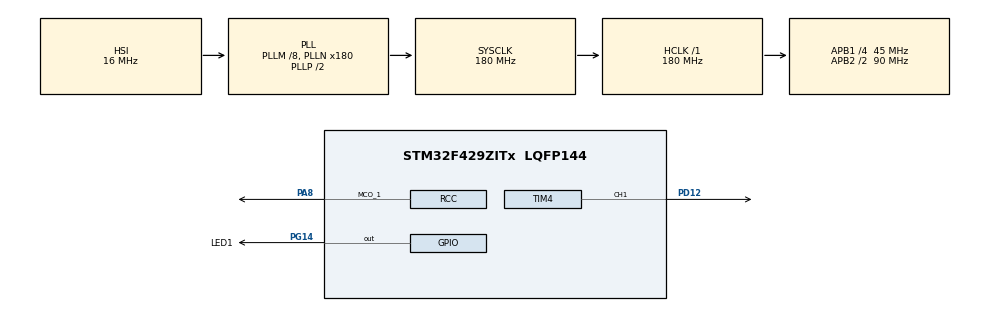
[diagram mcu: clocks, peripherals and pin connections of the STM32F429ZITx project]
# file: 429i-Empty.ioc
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Mcu.Family=STM32F4
Mcu.Name=STM32F429ZITx
Mcu.Package=LQFP144
NVIC.PriorityGroup=NVIC_PRIORITYGROUP_4
NVIC.TIM8_TRG_COM_TIM14_IRQn=true\:0\:0\:false\:false\:true\:true\:true\:true
PA13.Mode=Serial_Wire
PA13.Signal=SYS_JTMS-SWDIO
PA14.Mode=Serial_Wire
PA14.Signal=SYS_JTCK-SWCLK
PA8.Mode=Clock-out-1
PA8.Signal=RCC_MCO_1
PC14/OSC32_IN.Mode=LSE-External-Oscillator
PC14/OSC32_IN.Signal=RCC_OSC32_IN
PC15/OSC32_OUT.Mode=LSE-External-Oscillator
PC15/OSC32_OUT.Signal=RCC_OSC32_OUT
PD12.Signal=S_TIM4_CH1
PG13.Signal=EVENTOUT
PG14.GPIO_Label=LED1
PG14.Signal=GPIO_Output
PH0/OSC_IN.Mode=HSE-External-Oscillator
PH0/OSC_IN.Signal=RCC_OSC_IN
PH1/OSC_OUT.Mode=HSE-External-Oscillator
PH1/OSC_OUT.Signal=RCC_OSC_OUT
ProjectManager.HeapSize=0x200
ProjectManager.StackSize=0x400
ProjectManager.TargetToolchain=STM32CubeIDE
RCC.48MHZClocksFreq_Value=90000000
RCC.AHBFreq_Value=180000000
RCC.APB1CLKDivider=RCC_HCLK_DIV4
RCC.APB1Freq_Value=45000000
RCC.APB1TimFreq_Value=90000000
RCC.APB2CLKDivider=RCC_HCLK_DIV2
RCC.APB2Freq_Value=90000000
RCC.APB2TimFreq_Value=180000000
RCC.CortexFreq_Value=180000000
RCC.HCLKFreq_Value=180000000
RCC.HSE_VALUE=25000000
RCC.HSI_VALUE=16000000
RCC.PLLM=8
RCC.PLLN=180
RCC.RCC_MCO1Source=RCC_MCO1SOURCE_PLLCLK
RCC.RCC_MCODiv1=RCC_MCODIV_2
RCC.SYSCLKFreq_VALUE=180000000
RCC.SYSCLKSource=RCC_SYSCLKSOURCE_PLLCLK
RCC.VCOOutputFreq_Value=360000000
SH.S_TIM4_CH1.0=TIM4_CH1,PWM Generation1 CH1
TIM14.Prescaler=80-1
TIM4.Channel-PWM\ Generation1\ CH1=TIM_CHANNEL_1
TIM4.Prescaler=90
VP_TIM14_VS_ClockSourceINT.Mode=Enable_Timer
board=custom

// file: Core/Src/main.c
/* USER CODE BEGIN Header */
/**
 ******************************************************************************
 * @file           : main.c
 * @brief          : Main program body
 ******************************************************************************
 * @attention
 *
 * Copyright (c) 2023 STMicroelectronics.
 * All rights reserved.
 *
 * This software is licensed under terms that can be found in the LICENSE file
 * in the root directory of this software component.
 * If no LICENSE file comes with this software, it is provided AS-IS.
 *
 ******************************************************************************
 */
/* USER CODE END Header */
#include "main.h"

/* USER CODE BEGIN Includes */
#include <stdio.h>
/* USER CODE END Includes */

TIM_HandleTypeDef htim4;
TIM_HandleTypeDef htim14;

void SystemClock_Config(void);
static void MX_GPIO_Init(void);
static void MX_TIM14_Init(void);
static void MX_TIM4_Init(void);
/* USER CODE BEGIN PFP */
void HAL_TIM_PeriodElapsedCallback(TIM_HandleTypeDef *htim);
/* USER CODE END PFP */

int main(void) {

	/* MCU Configuration--------------------------------------------------------*/

	/* Reset of all peripherals, Initializes the Flash interface and the Systick. */
	HAL_Init();

	/* Configure the system clock */
	SystemClock_Config();

	/* Initialize all configured peripherals */
	MX_GPIO_Init();
	MX_TIM14_Init();
	MX_TIM4_Init();
	/* USER CODE BEGIN 2 */
	HAL_TIM_Base_Start_IT(&htim14);
	/* USER CODE END 2 */

	/* Infinite loop */
	/* USER CODE BEGIN WHILE */
	while (1) {
		printf("hello world!\n");
		HAL_Delay(100);
		/* USER CODE END WHILE */

	}
}

void SystemClock_Config(void) {
	RCC_OscInitTypeDef RCC_OscInitStruct = { 0 };
	RCC_ClkInitTypeDef RCC_ClkInitStruct = { 0 };

	/** Configure the main internal regulator output voltage
	 */
	__HAL_RCC_PWR_CLK_ENABLE();
	__HAL_PWR_VOLTAGESCALING_CONFIG(PWR_REGULATOR_VOLTAGE_SCALE1);

	/** Initializes the RCC Oscillators according to the specified parameters
	 * in the RCC_OscInitTypeDef structure.
	 */
	RCC_OscInitStruct.OscillatorType = RCC_OSCILLATORTYPE_HSI;
	RCC_OscInitStruct.HSIState = RCC_HSI_ON;
	RCC_OscInitStruct.HSICalibrationValue = RCC_HSICALIBRATION_DEFAULT;
	RCC_OscInitStruct.PLL.PLLState = RCC_PLL_ON;
	RCC_OscInitStruct.PLL.PLLSource = RCC_PLLSOURCE_HSI;
	RCC_OscInitStruct.PLL.PLLM = 8;
	RCC_OscInitStruct.PLL.PLLN = 180;
	RCC_OscInitStruct.PLL.PLLP = RCC_PLLP_DIV2;
	RCC_OscInitStruct.PLL.PLLQ = 4;
	if (HAL_RCC_OscConfig(&RCC_OscInitStruct) != HAL_OK) {
		Error_Handler();
	}

	/** Activate the Over-Drive mode
	 */
	if (HAL_PWREx_EnableOverDrive() != HAL_OK) {
		Error_Handler();
	}

	/** Initializes the CPU, AHB and APB buses clocks
	 */
	RCC_ClkInitStruct.ClockType = RCC_CLOCKTYPE_HCLK | RCC_CLOCKTYPE_SYSCLK
			| RCC_CLOCKTYPE_PCLK1 | RCC_CLOCKTYPE_PCLK2;
	RCC_ClkInitStruct.SYSCLKSource = RCC_SYSCLKSOURCE_PLLCLK;
	RCC_ClkInitStruct.AHBCLKDivider = RCC_SYSCLK_DIV1;
	RCC_ClkInitStruct.APB1CLKDivider = RCC_HCLK_DIV4;
	RCC_ClkInitStruct.APB2CLKDivider = RCC_HCLK_DIV2;

	if (HAL_RCC_ClockConfig(&RCC_ClkInitStruct, FLASH_LATENCY_5) != HAL_OK) {
		Error_Handler();
	}
	HAL_RCC_MCOConfig(RCC_MCO1, RCC_MCO1SOURCE_PLLCLK, RCC_MCODIV_2);
}

static void MX_TIM4_Init(void) {

	TIM_MasterConfigTypeDef sMasterConfig = { 0 };
	TIM_OC_InitTypeDef sConfigOC = { 0 };

	htim4.Instance = TIM4;
	htim4.Init.Prescaler = 90;
	htim4.Init.CounterMode = TIM_COUNTERMODE_UP;
	htim4.Init.Period = 65535;
	htim4.Init.ClockDivision = TIM_CLOCKDIVISION_DIV1;
	htim4.Init.AutoReloadPreload = TIM_AUTORELOAD_PRELOAD_DISABLE;
	if (HAL_TIM_PWM_Init(&htim4) != HAL_OK) {
		Error_Handler();
	}
	sMasterConfig.MasterOutputTrigger = TIM_TRGO_RESET;
	sMasterConfig.MasterSlaveMode = TIM_MASTERSLAVEMODE_DISABLE;
	if (HAL_TIMEx_MasterConfigSynchronization(&htim4, &sMasterConfig)
			!= HAL_OK) {
		Error_Handler();
	}
	sConfigOC.OCMode = TIM_OCMODE_PWM1;
	sConfigOC.Pulse = 0;
	sConfigOC.OCPolarity = TIM_OCPOLARITY_HIGH;
	sConfigOC.OCFastMode = TIM_OCFAST_DISABLE;
	if (HAL_TIM_PWM_ConfigChannel(&htim4, &sConfigOC, TIM_CHANNEL_1)
			!= HAL_OK) {
		Error_Handler();
	}
	HAL_TIM_MspPostInit(&htim4);

}

static void MX_TIM14_Init(void) {

	htim14.Instance = TIM14;
	htim14.Init.Prescaler = 80 - 1;
	htim14.Init.CounterMode = TIM_COUNTERMODE_UP;
	htim14.Init.Period = 65535;
	htim14.Init.ClockDivision = TIM_CLOCKDIVISION_DIV1;
	htim14.Init.AutoReloadPreload = TIM_AUTORELOAD_PRELOAD_DISABLE;
	if (HAL_TIM_Base_Init(&htim14) != HAL_OK) {
		Error_Handler();
	}

}

static void MX_GPIO_Init(void) {
	GPIO_InitTypeDef GPIO_InitStruct = { 0 };

	/* GPIO Ports Clock Enable */
	__HAL_RCC_GPIOC_CLK_ENABLE();
	__HAL_RCC_GPIOH_CLK_ENABLE();
	__HAL_RCC_GPIOD_CLK_ENABLE();
	__HAL_RCC_GPIOA_CLK_ENABLE();
	__HAL_RCC_GPIOG_CLK_ENABLE();

	/*Configure GPIO pin Output Level */
	HAL_GPIO_WritePin(LED1_GPIO_Port, LED1_Pin, GPIO_PIN_RESET);

	/*Configure GPIO pin : PA8 */
	GPIO_InitStruct.Pin = GPIO_PIN_8;
	GPIO_InitStruct.Mode = GPIO_MODE_AF_PP;
	GPIO_InitStruct.Pull = GPIO_NOPULL;
	GPIO_InitStruct.Speed = GPIO_SPEED_FREQ_LOW;
	GPIO_InitStruct.Alternate = GPIO_AF0_MCO;
	HAL_GPIO_Init(GPIOA, &GPIO_InitStruct);

	/*Configure GPIO pin : PG13 */
	GPIO_InitStruct.Pin = GPIO_PIN_13;
	GPIO_InitStruct.Mode = GPIO_MODE_AF_PP;
	GPIO_InitStruct.Pull = GPIO_NOPULL;
	GPIO_InitStruct.Speed = GPIO_SPEED_FREQ_LOW;
	GPIO_InitStruct.Alternate = GPIO_AF15_EVENTOUT;
	HAL_GPIO_Init(GPIOG, &GPIO_InitStruct);

	/*Configure GPIO pin : LED1_Pin */
	GPIO_InitStruct.Pin = LED1_Pin;
	GPIO_InitStruct.Mode = GPIO_MODE_OUTPUT_PP;
	GPIO_InitStruct.Pull = GPIO_NOPULL;
	GPIO_InitStruct.Speed = GPIO_SPEED_FREQ_LOW;
	HAL_GPIO_Init(LED1_GPIO_Port, &GPIO_InitStruct);

}

/* USER CODE BEGIN 4 */
/**
 * @brief  Period elapsed callback in non blocking mode
 * @note   This function is called  when TIM6 interrupt took place, inside
 * HAL_TIM_IRQHandler(). It makes a direct call to HAL_IncTick() to increment
 * a global variable "uwTick" used as application time base.
 * @param  htim : TIM handle
 * @retval None
 */
void HAL_TIM_PeriodElapsedCallback(TIM_HandleTypeDef *htim) {
	/* USER CODE BEGIN Callback 0 */

	/* USER CODE END Callback 0 */

	/* USER CODE BEGIN Callback 1 */
	HAL_GPIO_TogglePin(GPIOG, LED1_Pin);
	printf("SWO test!\r\n");
	/* USER CODE END Callback 1 */
}

int __io_putchar(int ch) {
	// Write character to ITM ch.0
	ITM_SendChar(ch);
	return (ch);
}
/* USER CODE END 4 */

void Error_Handler(void) {
	__disable_irq();
	while (1) {
	}
}
